# STM32WBA65xx register map
File version: 1.0
Registers are 32-bit, read-write, reset 0x0 unless marked. A register's access mark holds for its fields unless they carry their own. Offsets are from the block's base; [hi:lo] are bit positions.

## GTZC_TZSC — Global TrustZone Controller
Base 0x40032400
0x00 CR — TZSC control register
  [0] LCK — GTZC Secure and privilege configurations lock
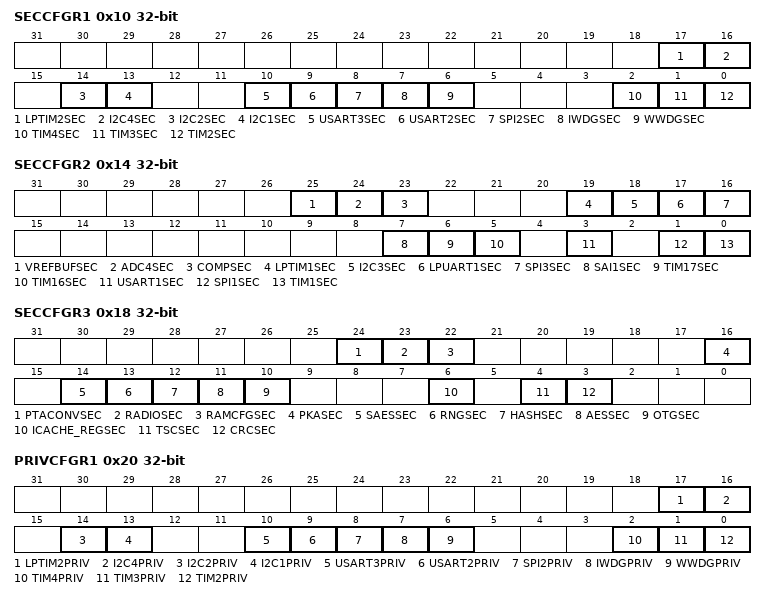
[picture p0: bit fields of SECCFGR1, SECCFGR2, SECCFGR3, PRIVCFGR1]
0x10 SECCFGR1 — TZSC secure configuration register 1
  [17] LPTIM2SEC — secure access mode for LPTIM2
  [16] I2C4SEC — secure access mode for I2C4
  [14] I2C2SEC — secure access mode for I2C2
  [13] I2C1SEC — secure access mode for I2C1
  [10] USART3SEC — secure access mode for USART3
  [9] USART2SEC — secure access mode for USART2
  [8] SPI2SEC — secure access mode for IWDG
  [7] IWDGSEC — secure access mode for IWDG
  [6] WWDGSEC — secure access mode for WWDG
  [2] TIM4SEC — secure access mode for TIM4
  [1] TIM3SEC — secure access mode for TIM3
  [0] TIM2SEC — secure access mode for TIM2
0x14 SECCFGR2 — TZSC secure configuration register 2
  [25] VREFBUFSEC — secure access mode for VREFBUF
  [24] ADC4SEC — secure access mode for ADC4
  [23] COMPSEC — secure access mode for COMP
  [19] LPTIM1SEC — secure access mode for LPTIM1
  [18] I2C3SEC — secure access mode for I2C3
  [17] LPUART1SEC — secure access mode for LPUART1
  [16] SPI3SEC — secure access mode for SPI3
  [7] SAI1SEC — secure access mode for SAI1
  [6] TIM17SEC — secure access mode for TIM17
  [5] TIM16SEC — secure access mode for TIM16
  [3] USART1SEC — secure access mode for USART1
  [1] SPI1SEC — secure access mode for SPI1
  [0] TIM1SEC — secure access mode for TIM1
0x18 SECCFGR3 — TZSC secure configuration register 3
  [24] PTACONVSEC — secure access mode for PTACONV
  [23] RADIOSEC — secure access mode for 2.4 GHz RADIO
  [22] RAMCFGSEC — secure access mode for RAMCFG
  [16] PKASEC — secure access mode for PKA
  [14] SAESSEC — secure access mode for SAES
  [13] RNGSEC — secure access mode for RNG
  [12] HASHSEC — secure access mode for HASH
  [11] AESSEC — secure access mode for AES
  [10] OTGSEC — secure access mode for OTG
  [6] ICACHE_REGSEC — secure access mode for ICACHE_REG
  [4] TSCSEC — secure access mode for TSC
  [3] CRCSEC — secure access mode for CRC
0x20 PRIVCFGR1 — TZSC privilege configuration register 1
  [17] LPTIM2PRIV — privileged access mode for LPTIM2
  [16] I2C4PRIV — privileged access mode for I2C4
  [14] I2C2PRIV — privileged access mode for I2C2
  [13] I2C1PRIV — privileged access mode for I2C1
  [10] USART3PRIV — privileged access mode for USART3
  [9] USART2PRIV — privileged access mode for USART2
  [8] SPI2PRIV — privileged access mode for IWDG
  [7] IWDGPRIV — privileged access mode for IWDG
  [6] WWDGPRIV — privileged access mode for WWDG
  [2] TIM4PRIV — privileged access mode for TIM4
  [1] TIM3PRIV — privileged access mode for TIM3
  [0] TIM2PRIV — privileged access mode for TIM2
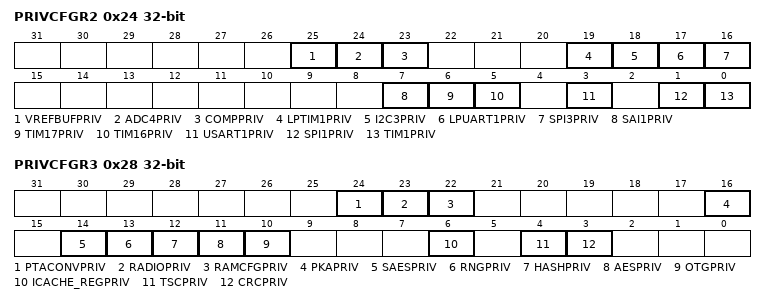
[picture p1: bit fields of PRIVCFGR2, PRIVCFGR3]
0x24 PRIVCFGR2 — TZSC privilege configuration register 2
  [25] VREFBUFPRIV — privileged access mode for VREFBUF
  [24] ADC4PRIV — privileged access mode for ADC4
  [23] COMPPRIV — privileged access mode for COMP
  [19] LPTIM1PRIV — privileged access mode for LPTIM1
  [18] I2C3PRIV — privileged access mode for I2C3
  [17] LPUART1PRIV — privileged access mode for LPUART1
  [16] SPI3PRIV — privileged access mode for SPI3
  [7] SAI1PRIV — privileged access mode for SAI1
  [6] TIM17PRIV — privileged access mode for TIM17
  [5] TIM16PRIV — privileged access mode for TIM16
  [3] USART1PRIV — privileged access mode for USART1
  [1] SPI1PRIV — privileged access mode for SPI1
  [0] TIM1PRIV — privileged access mode for TIM1
0x28 PRIVCFGR3 — TZSC privilege configuration register 3
  [24] PTACONVPRIV — privileged access mode for PTACONV
  [23] RADIOPRIV — privileged access mode for 2.4 GHz RADIO
  [22] RAMCFGPRIV — privileged access mode for RAMCFG
  [16] PKAPRIV — privileged access mode for PKA
  [14] SAESPRIV — privileged access mode for SAES
  [13] RNGPRIV — privileged access mode for RNG
  [12] HASHPRIV — privileged access mode for HASH
  [11] AESPRIV — privileged access mode for AES
  [10] OTGPRIV — privileged access mode for OTG
  [6] ICACHE_REGPRIV — privileged access mode for ICACHE_REG
  [4] TSCPRIV — privileged access mode for TSC
  [3] CRCPRIV — privileged access mode for CRC
